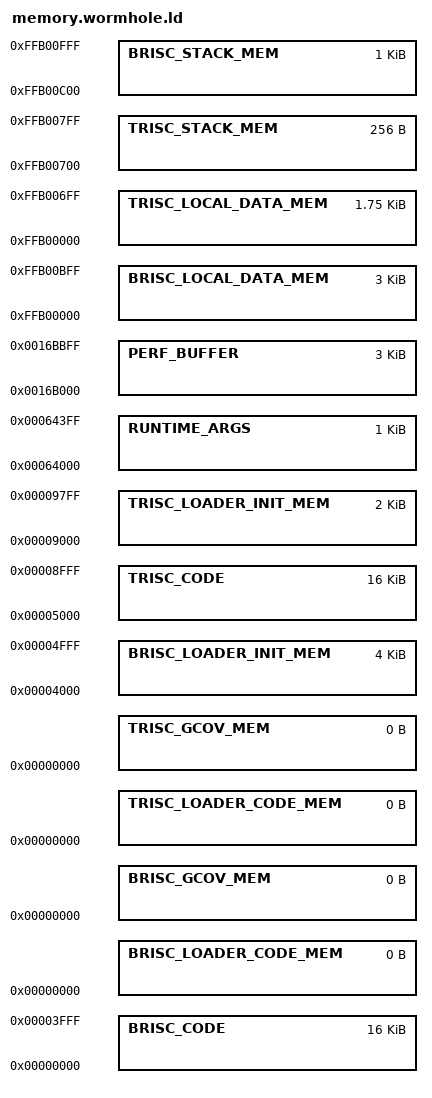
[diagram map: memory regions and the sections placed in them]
/*
 * SPDX-FileCopyrightText: (c) 2025 Tenstorrent AI ULC
 *
 * SPDX-License-Identifier: Apache-2.0
 */

LOCAL_MEM_BASE = 0xFFB00000;
BRISC_LOCAL_MEM_LENGTH = 4K;
TRISC_LOCAL_MEM_LENGTH = 2K;
NCRISC_LOCAL_MEM_LENGTH = 4K;

NCRISC_IMEM = 0xFFC00000;
NCRISC_IMEM_LENGTH = 16K;

L1_BASE = 0x0;
RUNTIME_ARGS_START = 0x64000;
PERF_BUFFER_START = 0x16B000;
UNDEFINED = 0;

/* The address space layout goes as follows:
 * [BRISC] [TRISCs] [NCRISC] (...) [LOCAL_MEM]
 * LOADER_INIT regions are defined for every core, as the data segment resides in LOCAL_MEM.
 * LOADER_CODE regions are undefined for all cores excepting the NCRISC, as its code resides in its IMEM.
 * GCOV region is left undefined for obvious reasons.
 */

MEMORY
{
    /* Private memory layout for each core */
    BRISC_LOCAL_DATA_MEM    : ORIGIN = LOCAL_MEM_BASE, LENGTH = 3K
    BRISC_STACK_MEM         : ORIGIN = ORIGIN(BRISC_LOCAL_DATA_MEM) + LENGTH(BRISC_LOCAL_DATA_MEM), LENGTH = BRISC_LOCAL_MEM_LENGTH - LENGTH(BRISC_LOCAL_DATA_MEM)

    TRISC_LOCAL_DATA_MEM   : ORIGIN = LOCAL_MEM_BASE, LENGTH = 1792
    TRISC_STACK_MEM        : ORIGIN = ORIGIN(TRISC_LOCAL_DATA_MEM) + LENGTH(TRISC_LOCAL_DATA_MEM), LENGTH = TRISC_LOCAL_MEM_LENGTH - LENGTH(TRISC_LOCAL_DATA_MEM)

    /* L1 layout */
    BRISC_CODE              : ORIGIN = L1_BASE, LENGTH = 16K
    BRISC_LOADER_INIT_MEM   : ORIGIN = ORIGIN(BRISC_CODE) + LENGTH(BRISC_CODE), LENGTH = BRISC_LOCAL_MEM_LENGTH

    TRISC_CODE             : ORIGIN = ORIGIN(BRISC_LOADER_INIT_MEM) + LENGTH(BRISC_LOADER_INIT_MEM), LENGTH = 16K
    TRISC_LOADER_INIT_MEM  : ORIGIN = ORIGIN(TRISC_CODE) + LENGTH(TRISC_CODE), LENGTH = TRISC_LOCAL_MEM_LENGTH

    RUNTIME_ARGS            : ORIGIN = RUNTIME_ARGS_START, LENGTH = 1K
    PERF_BUFFER             : ORIGIN = PERF_BUFFER_START, LENGTH = 3K


    /* (discarded) */
    BRISC_LOADER_CODE_MEM   : ORIGIN = UNDEFINED, LENGTH = UNDEFINED
    BRISC_GCOV_MEM          : ORIGIN = UNDEFINED, LENGTH = UNDEFINED

    TRISC_LOADER_CODE_MEM  : ORIGIN = UNDEFINED, LENGTH = UNDEFINED
    TRISC_GCOV_MEM         : ORIGIN = UNDEFINED, LENGTH = UNDEFINED
}
PROVIDE(__instrn_buffer = 0xFFE40000);
